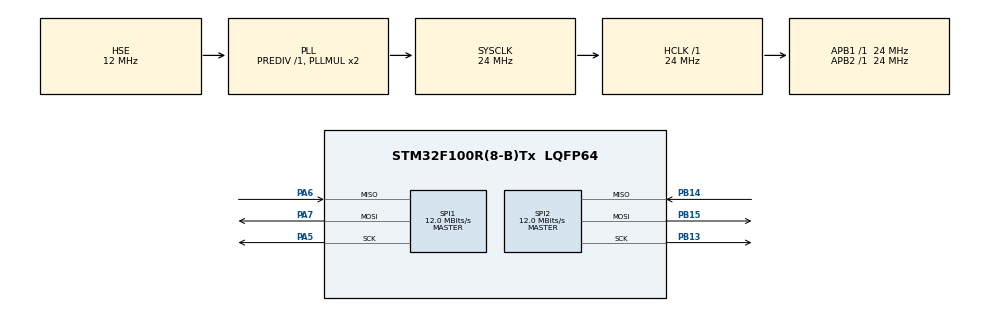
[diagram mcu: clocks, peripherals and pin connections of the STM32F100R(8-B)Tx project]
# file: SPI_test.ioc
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Dma.Request0=SPI1_TX
Dma.Request1=SPI1_RX
Dma.SPI1_RX.1.Direction=DMA_PERIPH_TO_MEMORY
Dma.SPI1_RX.1.Instance=DMA1_Channel2
Dma.SPI1_RX.1.MemDataAlignment=DMA_MDATAALIGN_BYTE
Dma.SPI1_RX.1.MemInc=DMA_MINC_ENABLE
Dma.SPI1_RX.1.Mode=DMA_NORMAL
Dma.SPI1_RX.1.PeriphDataAlignment=DMA_PDATAALIGN_BYTE
Dma.SPI1_RX.1.PeriphInc=DMA_PINC_DISABLE
Dma.SPI1_RX.1.Priority=DMA_PRIORITY_LOW
Dma.SPI1_TX.0.Direction=DMA_MEMORY_TO_PERIPH
Dma.SPI1_TX.0.Instance=DMA1_Channel3
Dma.SPI1_TX.0.MemDataAlignment=DMA_MDATAALIGN_BYTE
Dma.SPI1_TX.0.MemInc=DMA_MINC_ENABLE
Dma.SPI1_TX.0.Mode=DMA_NORMAL
Dma.SPI1_TX.0.PeriphDataAlignment=DMA_PDATAALIGN_BYTE
Dma.SPI1_TX.0.PeriphInc=DMA_PINC_DISABLE
Dma.SPI1_TX.0.Priority=DMA_PRIORITY_LOW
Mcu.Family=STM32F1
Mcu.Name=STM32F100R(8-B)Tx
Mcu.Package=LQFP64
NVIC.DMA1_Channel2_IRQn=true\:0\:0\:false\:false\:true\:false\:true\:true
NVIC.DMA1_Channel3_IRQn=true\:0\:0\:false\:false\:true\:false\:true\:true
NVIC.PriorityGroup=NVIC_PRIORITYGROUP_4
PA0-WKUP.Mode=SYS_WakeUp0
PA0-WKUP.Signal=SYS_WKUP
PA13.GPIO_Label=TMS_SWDIO
PA13.Mode=Serial_Wire
PA13.Signal=SYS_JTMS-SWDIO
PA14.GPIO_Label=TCK_SWCLK
PA14.Mode=Serial_Wire
PA14.Signal=SYS_JTCK-SWCLK
PA5.Mode=Full_Duplex_Master
PA5.Signal=SPI1_SCK
PA6.Mode=Full_Duplex_Master
PA6.Signal=SPI1_MISO
PA7.Mode=Full_Duplex_Master
PA7.Signal=SPI1_MOSI
PB13.Mode=Full_Duplex_Master
PB13.Signal=SPI2_SCK
PB14.Mode=Full_Duplex_Master
PB14.Signal=SPI2_MISO
PB15.Mode=Full_Duplex_Master
PB15.Signal=SPI2_MOSI
PC14-OSC32_IN.Mode=LSE-External-Oscillator
PC14-OSC32_IN.Signal=RCC_OSC32_IN
PC15-OSC32_OUT.Mode=LSE-External-Oscillator
PC15-OSC32_OUT.Signal=RCC_OSC32_OUT
PD0-OSC_IN.Mode=HSE-External-Oscillator
PD0-OSC_IN.Signal=RCC_OSC_IN
PD1-OSC_OUT.Mode=HSE-External-Oscillator
PD1-OSC_OUT.Signal=RCC_OSC_OUT
ProjectManager.HeapSize=0x200
ProjectManager.StackSize=0x400
ProjectManager.TargetToolchain=STM32CubeIDE
RCC.AHBFreq_Value=24000000
RCC.APB1Freq_Value=24000000
RCC.APB1TimFreq_Value=24000000
RCC.APB2Freq_Value=24000000
RCC.APB2TimFreq_Value=24000000
RCC.HCLKFreq_Value=24000000
RCC.HSE_VALUE=12000000
RCC.PLLSource=RCC_PLLSOURCE_HSE
RCC.SYSCLKFreq_VALUE=24000000
RCC.SYSCLKSource=RCC_SYSCLKSOURCE_PLLCLK
SPI1.BaudRatePrescaler=SPI_BAUDRATEPRESCALER_2
SPI1.CalculateBaudRate=12.0 MBits/s
SPI1.Direction=SPI_DIRECTION_2LINES
SPI1.Mode=SPI_MODE_MASTER
SPI1.VirtualType=VM_MASTER
SPI2.CalculateBaudRate=12.0 MBits/s
SPI2.Direction=SPI_DIRECTION_2LINES
SPI2.Mode=SPI_MODE_MASTER
SPI2.VirtualType=VM_MASTER
board=STM32VLDISCOVERY

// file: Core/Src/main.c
/* USER CODE BEGIN Header */
/**
  ******************************************************************************
  * @file           : main.c
  * @brief          : Main program body
  ******************************************************************************
  * @attention
  *
  * Copyright (c) 2023 STMicroelectronics.
  * All rights reserved.
  *
  * This software is licensed under terms that can be found in the LICENSE file
  * in the root directory of this software component.
  * If no LICENSE file comes with this software, it is provided AS-IS.
  *
  ******************************************************************************
  */
/* USER CODE END Header */
#include "main.h"

/* USER CODE BEGIN PD */
#define BUFFER_SIZE 10
/* USER CODE END PD */

SPI_HandleTypeDef hspi1;
SPI_HandleTypeDef hspi2;
DMA_HandleTypeDef hdma_spi1_tx;
DMA_HandleTypeDef hdma_spi1_rx;

/* USER CODE BEGIN PV */
uint8_t transmitBuffer[BUFFER_SIZE];
uint8_t receiveBuffer[BUFFER_SIZE];
/* USER CODE END PV */

void SystemClock_Config(void);
static void MX_GPIO_Init(void);
static void MX_DMA_Init(void);
static void MX_SPI1_Init(void);
static void MX_SPI2_Init(void);

int main(void)
{

  /* MCU Configuration--------------------------------------------------------*/

  /* Reset of all peripherals, Initializes the Flash interface and the Systick. */
  HAL_Init();

  /* Configure the system clock */
  SystemClock_Config();

  /* Initialize all configured peripherals */
  MX_GPIO_Init();
  MX_DMA_Init();
  MX_SPI1_Init();
  MX_SPI2_Init();

  /* Infinite loop */
  while (1)
  {
	  for (int i = 0; i < BUFFER_SIZE; i++) {
	          transmitBuffer[i] = i;
	          receiveBuffer[i] = i + 10;
	  }

	  HAL_SPI_TransmitReceive_DMA(&hspi1, transmitBuffer, receiveBuffer, BUFFER_SIZE);

	  while (HAL_SPI_GetState(&hspi1) != HAL_SPI_STATE_READY);

	  HAL_SPI_TransmitReceive_DMA(&hspi2, receiveBuffer, transmitBuffer, BUFFER_SIZE);

	  while (HAL_SPI_GetState(&hspi2) != HAL_SPI_STATE_READY);
  }
}

void SystemClock_Config(void)
{
  RCC_OscInitTypeDef RCC_OscInitStruct = {0};
  RCC_ClkInitTypeDef RCC_ClkInitStruct = {0};

  /** Initializes the RCC Oscillators according to the specified parameters
  * in the RCC_OscInitTypeDef structure.
  */
  RCC_OscInitStruct.OscillatorType = RCC_OSCILLATORTYPE_HSE;
  RCC_OscInitStruct.HSEState = RCC_HSE_ON;
  RCC_OscInitStruct.HSEPredivValue = RCC_HSE_PREDIV_DIV1;
  RCC_OscInitStruct.PLL.PLLState = RCC_PLL_ON;
  RCC_OscInitStruct.PLL.PLLSource = RCC_PLLSOURCE_HSE;
  RCC_OscInitStruct.PLL.PLLMUL = RCC_PLL_MUL2;
  if (HAL_RCC_OscConfig(&RCC_OscInitStruct) != HAL_OK)
  {
    Error_Handler();
  }

  /** Initializes the CPU, AHB and APB buses clocks
  */
  RCC_ClkInitStruct.ClockType = RCC_CLOCKTYPE_HCLK|RCC_CLOCKTYPE_SYSCLK
                              |RCC_CLOCKTYPE_PCLK1|RCC_CLOCKTYPE_PCLK2;
  RCC_ClkInitStruct.SYSCLKSource = RCC_SYSCLKSOURCE_PLLCLK;
  RCC_ClkInitStruct.AHBCLKDivider = RCC_SYSCLK_DIV1;
  RCC_ClkInitStruct.APB1CLKDivider = RCC_HCLK_DIV1;
  RCC_ClkInitStruct.APB2CLKDivider = RCC_HCLK_DIV1;

  if (HAL_RCC_ClockConfig(&RCC_ClkInitStruct, FLASH_LATENCY_0) != HAL_OK)
  {
    Error_Handler();
  }
}

static void MX_SPI1_Init(void)
{

  /* SPI1 parameter configuration*/
  hspi1.Instance = SPI1;
  hspi1.Init.Mode = SPI_MODE_MASTER;
  hspi1.Init.Direction = SPI_DIRECTION_2LINES;
  hspi1.Init.DataSize = SPI_DATASIZE_8BIT;
  hspi1.Init.CLKPolarity = SPI_POLARITY_LOW;
  hspi1.Init.CLKPhase = SPI_PHASE_1EDGE;
  hspi1.Init.NSS = SPI_NSS_SOFT;
  hspi1.Init.BaudRatePrescaler = SPI_BAUDRATEPRESCALER_2;
  hspi1.Init.FirstBit = SPI_FIRSTBIT_MSB;
  hspi1.Init.TIMode = SPI_TIMODE_DISABLE;
  hspi1.Init.CRCCalculation = SPI_CRCCALCULATION_DISABLE;
  hspi1.Init.CRCPolynomial = 10;
  if (HAL_SPI_Init(&hspi1) != HAL_OK)
  {
    Error_Handler();
  }

}

static void MX_SPI2_Init(void)
{

  /* SPI2 parameter configuration*/
  hspi2.Instance = SPI2;
  hspi2.Init.Mode = SPI_MODE_MASTER;
  hspi2.Init.Direction = SPI_DIRECTION_2LINES;
  hspi2.Init.DataSize = SPI_DATASIZE_8BIT;
  hspi2.Init.CLKPolarity = SPI_POLARITY_LOW;
  hspi2.Init.CLKPhase = SPI_PHASE_1EDGE;
  hspi2.Init.NSS = SPI_NSS_SOFT;
  hspi2.Init.BaudRatePrescaler = SPI_BAUDRATEPRESCALER_2;
  hspi2.Init.FirstBit = SPI_FIRSTBIT_MSB;
  hspi2.Init.TIMode = SPI_TIMODE_DISABLE;
  hspi2.Init.CRCCalculation = SPI_CRCCALCULATION_DISABLE;
  hspi2.Init.CRCPolynomial = 10;
  if (HAL_SPI_Init(&hspi2) != HAL_OK)
  {
    Error_Handler();
  }

}

static void MX_DMA_Init(void)
{

  /* DMA controller clock enable */
  __HAL_RCC_DMA1_CLK_ENABLE();

  /* DMA interrupt init */
  /* DMA1_Channel2_IRQn interrupt configuration */
  HAL_NVIC_SetPriority(DMA1_Channel2_IRQn, 0, 0);
  HAL_NVIC_EnableIRQ(DMA1_Channel2_IRQn);
  /* DMA1_Channel3_IRQn interrupt configuration */
  HAL_NVIC_SetPriority(DMA1_Channel3_IRQn, 0, 0);
  HAL_NVIC_EnableIRQ(DMA1_Channel3_IRQn);

}

static void MX_GPIO_Init(void)
{

  /* GPIO Ports Clock Enable */
  __HAL_RCC_GPIOC_CLK_ENABLE();
  __HAL_RCC_GPIOD_CLK_ENABLE();
  __HAL_RCC_GPIOA_CLK_ENABLE();
  __HAL_RCC_GPIOB_CLK_ENABLE();

}

void Error_Handler(void)
{
  __disable_irq();
  while (1)
  {
  }
}
